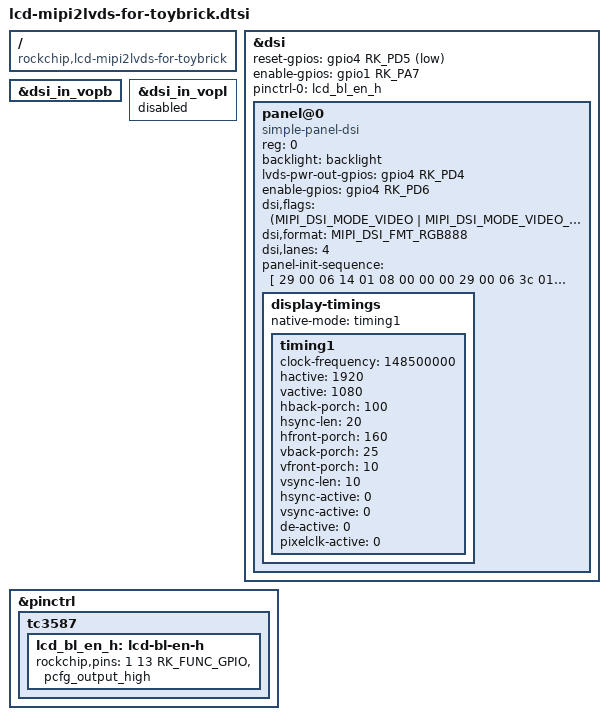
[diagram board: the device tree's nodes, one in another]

/ {
	compatible = "rockchip,lcd-mipi2lvds-for-toybrick","rockchip,rk3399pro";
};

&dsi {
	reset-gpios = <&gpio4 RK_PD5 GPIO_ACTIVE_LOW>;	/* TC358775_RST */
	enable-gpios = <&gpio1 RK_PA7 GPIO_ACTIVE_HIGH>; /* STBY */
	status = "okay";
	pinctrl-names = "default";
	pinctrl-0 = <&lcd_bl_en_h>;
	panel@0 {
		compatible = "simple-panel-dsi";
		reg = <0>;
		backlight = <&backlight>;
		lvds-pwr-out-gpios = <&gpio4 RK_PD4 GPIO_ACTIVE_HIGH>; /* LVDS_PANEL_PWREN */
		enable-gpios = <&gpio4 RK_PD6 GPIO_ACTIVE_HIGH>; /* LCD_PWREN_H */
		dsi,flags = <(MIPI_DSI_MODE_VIDEO | MIPI_DSI_MODE_VIDEO_BURST |
				MIPI_DSI_MODE_LPM | MIPI_DSI_MODE_EOT_PACKET)>;
		dsi,format = <MIPI_DSI_FMT_RGB888>;
		dsi,lanes = <4>;

		panel-init-sequence = [
			29 00 06 14 01 08 00 00 00
			29 00 06 3c 01 0c 00 0a 00
			29 00 06 64 01 0c 00 00 00
			29 00 06 68 01 0c 00 00 00
			29 00 06 6c 01 0c 00 00 00
			29 00 06 70 01 0c 00 00 00
			29 00 06 34 01 1f 00 00 00
			29 00 06 10 02 1f 00 00 00
			29 00 06 04 01 01 00 00 00
			29 00 06 04 02 01 00 00 00
			29 00 06 50 04 00 01 f0 03
			29 00 06 54 04 14 00 64 00
			29 00 06 58 04 80 07 a0 00
			29 00 06 5c 04 0a 00 19 00
			29 00 06 60 04 38 04 0a 00
			29 00 06 64 04 01 00 00 00
			29 00 06 a0 04 06 c0 00 00
			29 00 06 04 05 04 00 00 00
			29 00 06 80 04 00 01 02 03
			29 00 06 84 04 04 07 05 08
			29 00 06 88 04 09 0a 0e 0f
			29 00 06 8c 04 0b 0c 0d 10
			29 00 06 90 04 16 17 11 12
			29 00 06 94 04 13 14 15 1b
			29 14 06 98 04 18 19 1a 06
			29 78 06 9c 04 33 04 00 00
		];

		display-timings {
			native-mode = <&timing1>;

			timing1: timing1 {
				clock-frequency = <148500000>;
				hactive = <1920>;
				vactive = <1080>;
				hback-porch = <100>;
				hsync-len = <20>;
				hfront-porch = <160>;
				vback-porch = <25>;
				vfront-porch = <10>;
				vsync-len = <10>;
				hsync-active = <0>;
				vsync-active = <0>;
				de-active = <0>;
				pixelclk-active = <0>;
			};
		};
	};
};

&dsi_in_vopb {
	status = "okay";
};

&dsi_in_vopl {
	status = "disabled";
};

&pinctrl {
	tc3587 {
		lcd_bl_en_h: lcd-bl-en-h {
			rockchip,pins =
				<1 13 RK_FUNC_GPIO &pcfg_output_high>;
		};
	};
};
